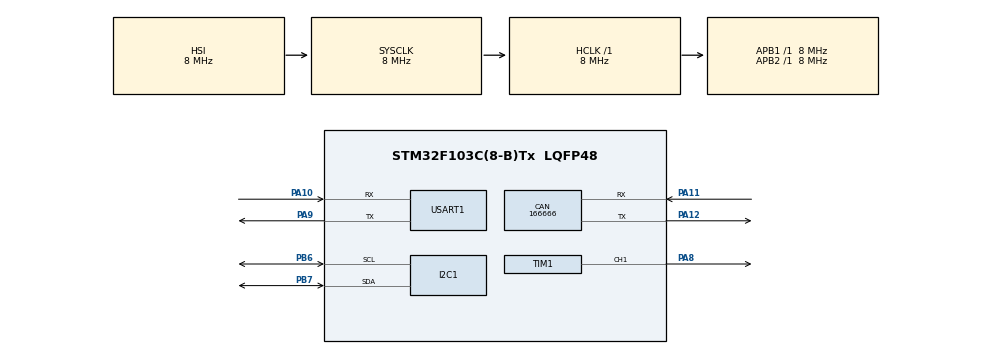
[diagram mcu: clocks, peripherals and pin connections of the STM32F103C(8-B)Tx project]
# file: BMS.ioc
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CAN.BS1=CAN_BS1_1TQ
CAN.BS2=CAN_BS2_1TQ
CAN.CalculateBaudRate=166666
CAN.CalculateTimeBit=6000
CAN.CalculateTimeQuantum=2000.0
Mcu.Family=STM32F1
Mcu.Name=STM32F103C(8-B)Tx
Mcu.Package=LQFP48
NVIC.PriorityGroup=NVIC_PRIORITYGROUP_4
PA10.Mode=Asynchronous
PA10.Signal=USART1_RX
PA11.Mode=CAN_Activate
PA11.Signal=CAN_RX
PA12.Mode=CAN_Activate
PA12.Signal=CAN_TX
PA8.Signal=S_TIM1_CH1
PA9.Mode=Asynchronous
PA9.Signal=USART1_TX
PB6.Mode=I2C
PB6.Signal=I2C1_SCL
PB7.Mode=I2C
PB7.Signal=I2C1_SDA
ProjectManager.HeapSize=0x200
ProjectManager.StackSize=0x400
ProjectManager.TargetToolchain=STM32CubeIDE
RCC.AHBFreq_Value=8000000
RCC.APB1Freq_Value=8000000
RCC.APB1TimFreq_Value=8000000
RCC.APB2Freq_Value=8000000
RCC.APB2TimFreq_Value=8000000
RCC.HCLKFreq_Value=8000000
RCC.SYSCLKFreq_VALUE=8000000
RCC.USBFreq_Value=8000000
SH.S_TIM1_CH1.0=TIM1_CH1,PWM Generation1 CH1
TIM1.Channel-PWM\ Generation1\ CH1=TIM_CHANNEL_1
TIM1.Period=62499
TIM1.Prescaler=127
TIM1.Pulse-PWM\ Generation1\ CH1=20000
USART1.VirtualMode=VM_ASYNC
VP_SYS_VS_ND.Mode=No_Debug
board=custom

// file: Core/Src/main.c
/* USER CODE BEGIN Header */
/**
  ******************************************************************************
  * @file           : main.c
  * @brief          : Main program body
  ******************************************************************************
  * @attention
  *
  * Copyright (c) 2026 STMicroelectronics.
  * All rights reserved.
  *
  * This software is licensed under terms that can be found in the LICENSE file
  * in the root directory of this software component.
  * If no LICENSE file comes with this software, it is provided AS-IS.
  *
  ******************************************************************************
  */
/* USER CODE END Header */
#include "main.h"

CAN_HandleTypeDef hcan;

I2C_HandleTypeDef hi2c1;

TIM_HandleTypeDef htim1;

UART_HandleTypeDef huart1;

void SystemClock_Config(void);
static void MX_GPIO_Init(void);
static void MX_CAN_Init(void);
static void MX_I2C1_Init(void);
static void MX_TIM1_Init(void);
static void MX_USART1_UART_Init(void);

int main(void)
{

  /* MCU Configuration--------------------------------------------------------*/

  /* Reset of all peripherals, Initializes the Flash interface and the Systick. */
  HAL_Init();

  /* Configure the system clock */
  SystemClock_Config();

  /* Initialize all configured peripherals */
  MX_GPIO_Init();
  MX_CAN_Init();
  MX_I2C1_Init();
  MX_TIM1_Init();
  MX_USART1_UART_Init();

  /* Infinite loop */
  while (1)
  {

    /* USER CODE BEGIN 3 */

	  // Hello
  }
  /* USER CODE END 3 */
}

void SystemClock_Config(void)
{
  RCC_OscInitTypeDef RCC_OscInitStruct = {0};
  RCC_ClkInitTypeDef RCC_ClkInitStruct = {0};

  /** Initializes the RCC Oscillators according to the specified parameters
  * in the RCC_OscInitTypeDef structure.
  */
  RCC_OscInitStruct.OscillatorType = RCC_OSCILLATORTYPE_HSI;
  RCC_OscInitStruct.HSIState = RCC_HSI_ON;
  RCC_OscInitStruct.HSICalibrationValue = RCC_HSICALIBRATION_DEFAULT;
  RCC_OscInitStruct.PLL.PLLState = RCC_PLL_NONE;
  if (HAL_RCC_OscConfig(&RCC_OscInitStruct) != HAL_OK)
  {
    Error_Handler();
  }

  /** Initializes the CPU, AHB and APB buses clocks
  */
  RCC_ClkInitStruct.ClockType = RCC_CLOCKTYPE_HCLK|RCC_CLOCKTYPE_SYSCLK
                              |RCC_CLOCKTYPE_PCLK1|RCC_CLOCKTYPE_PCLK2;
  RCC_ClkInitStruct.SYSCLKSource = RCC_SYSCLKSOURCE_HSI;
  RCC_ClkInitStruct.AHBCLKDivider = RCC_SYSCLK_DIV1;
  RCC_ClkInitStruct.APB1CLKDivider = RCC_HCLK_DIV1;
  RCC_ClkInitStruct.APB2CLKDivider = RCC_HCLK_DIV1;

  if (HAL_RCC_ClockConfig(&RCC_ClkInitStruct, FLASH_LATENCY_0) != HAL_OK)
  {
    Error_Handler();
  }
}

static void MX_CAN_Init(void)
{

  hcan.Instance = CAN1;
  hcan.Init.Prescaler = 16;
  hcan.Init.Mode = CAN_MODE_NORMAL;
  hcan.Init.SyncJumpWidth = CAN_SJW_1TQ;
  hcan.Init.TimeSeg1 = CAN_BS1_1TQ;
  hcan.Init.TimeSeg2 = CAN_BS2_1TQ;
  hcan.Init.TimeTriggeredMode = DISABLE;
  hcan.Init.AutoBusOff = DISABLE;
  hcan.Init.AutoWakeUp = DISABLE;
  hcan.Init.AutoRetransmission = DISABLE;
  hcan.Init.ReceiveFifoLocked = DISABLE;
  hcan.Init.TransmitFifoPriority = DISABLE;
  if (HAL_CAN_Init(&hcan) != HAL_OK)
  {
    Error_Handler();
  }

}

static void MX_I2C1_Init(void)
{

  hi2c1.Instance = I2C1;
  hi2c1.Init.ClockSpeed = 100000;
  hi2c1.Init.DutyCycle = I2C_DUTYCYCLE_2;
  hi2c1.Init.OwnAddress1 = 0;
  hi2c1.Init.AddressingMode = I2C_ADDRESSINGMODE_7BIT;
  hi2c1.Init.DualAddressMode = I2C_DUALADDRESS_DISABLE;
  hi2c1.Init.OwnAddress2 = 0;
  hi2c1.Init.GeneralCallMode = I2C_GENERALCALL_DISABLE;
  hi2c1.Init.NoStretchMode = I2C_NOSTRETCH_DISABLE;
  if (HAL_I2C_Init(&hi2c1) != HAL_OK)
  {
    Error_Handler();
  }

}

static void MX_TIM1_Init(void)
{

  TIM_MasterConfigTypeDef sMasterConfig = {0};
  TIM_OC_InitTypeDef sConfigOC = {0};
  TIM_BreakDeadTimeConfigTypeDef sBreakDeadTimeConfig = {0};

  htim1.Instance = TIM1;
  htim1.Init.Prescaler = 127;
  htim1.Init.CounterMode = TIM_COUNTERMODE_UP;
  htim1.Init.Period = 62499;
  htim1.Init.ClockDivision = TIM_CLOCKDIVISION_DIV1;
  htim1.Init.RepetitionCounter = 0;
  htim1.Init.AutoReloadPreload = TIM_AUTORELOAD_PRELOAD_DISABLE;
  if (HAL_TIM_PWM_Init(&htim1) != HAL_OK)
  {
    Error_Handler();
  }
  sMasterConfig.MasterOutputTrigger = TIM_TRGO_RESET;
  sMasterConfig.MasterSlaveMode = TIM_MASTERSLAVEMODE_DISABLE;
  if (HAL_TIMEx_MasterConfigSynchronization(&htim1, &sMasterConfig) != HAL_OK)
  {
    Error_Handler();
  }
  sConfigOC.OCMode = TIM_OCMODE_PWM1;
  sConfigOC.Pulse = 20000;
  sConfigOC.OCPolarity = TIM_OCPOLARITY_HIGH;
  sConfigOC.OCNPolarity = TIM_OCNPOLARITY_HIGH;
  sConfigOC.OCFastMode = TIM_OCFAST_DISABLE;
  sConfigOC.OCIdleState = TIM_OCIDLESTATE_RESET;
  sConfigOC.OCNIdleState = TIM_OCNIDLESTATE_RESET;
  if (HAL_TIM_PWM_ConfigChannel(&htim1, &sConfigOC, TIM_CHANNEL_1) != HAL_OK)
  {
    Error_Handler();
  }
  sBreakDeadTimeConfig.OffStateRunMode = TIM_OSSR_DISABLE;
  sBreakDeadTimeConfig.OffStateIDLEMode = TIM_OSSI_DISABLE;
  sBreakDeadTimeConfig.LockLevel = TIM_LOCKLEVEL_OFF;
  sBreakDeadTimeConfig.DeadTime = 0;
  sBreakDeadTimeConfig.BreakState = TIM_BREAK_DISABLE;
  sBreakDeadTimeConfig.BreakPolarity = TIM_BREAKPOLARITY_HIGH;
  sBreakDeadTimeConfig.AutomaticOutput = TIM_AUTOMATICOUTPUT_DISABLE;
  if (HAL_TIMEx_ConfigBreakDeadTime(&htim1, &sBreakDeadTimeConfig) != HAL_OK)
  {
    Error_Handler();
  }
  HAL_TIM_MspPostInit(&htim1);

}

static void MX_USART1_UART_Init(void)
{

  huart1.Instance = USART1;
  huart1.Init.BaudRate = 115200;
  huart1.Init.WordLength = UART_WORDLENGTH_8B;
  huart1.Init.StopBits = UART_STOPBITS_1;
  huart1.Init.Parity = UART_PARITY_NONE;
  huart1.Init.Mode = UART_MODE_TX_RX;
  huart1.Init.HwFlowCtl = UART_HWCONTROL_NONE;
  huart1.Init.OverSampling = UART_OVERSAMPLING_16;
  if (HAL_UART_Init(&huart1) != HAL_OK)
  {
    Error_Handler();
  }

}

static void MX_GPIO_Init(void)
{

  /* GPIO Ports Clock Enable */
  __HAL_RCC_GPIOA_CLK_ENABLE();
  __HAL_RCC_GPIOB_CLK_ENABLE();

}

void Error_Handler(void)
{
  __disable_irq();
  while (1)
  {
  }
}
